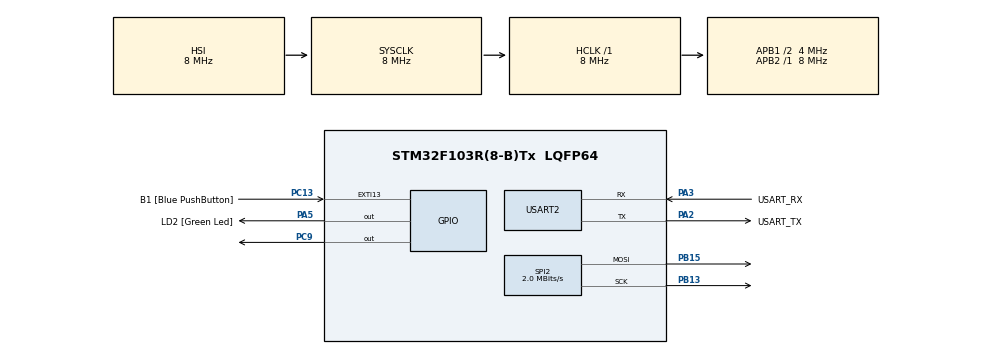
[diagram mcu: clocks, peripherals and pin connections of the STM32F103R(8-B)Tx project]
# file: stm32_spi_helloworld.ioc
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Dma.Request0=SPI2_TX
Dma.SPI2_TX.0.Direction=DMA_MEMORY_TO_PERIPH
Dma.SPI2_TX.0.Instance=DMA1_Channel5
Dma.SPI2_TX.0.MemDataAlignment=DMA_MDATAALIGN_BYTE
Dma.SPI2_TX.0.MemInc=DMA_MINC_ENABLE
Dma.SPI2_TX.0.Mode=DMA_NORMAL
Dma.SPI2_TX.0.PeriphDataAlignment=DMA_PDATAALIGN_BYTE
Dma.SPI2_TX.0.PeriphInc=DMA_PINC_DISABLE
Dma.SPI2_TX.0.Priority=DMA_PRIORITY_LOW
Mcu.Family=STM32F1
Mcu.Name=STM32F103R(8-B)Tx
Mcu.Package=LQFP64
NVIC.DMA1_Channel5_IRQn=true\:0\:0\:false\:false\:true\:false
NVIC.EXTI15_10_IRQn=true\:0\:0\:false\:false\:true\:true
NVIC.PriorityGroup=NVIC_PRIORITYGROUP_4
PA13.GPIO_Label=TMS
PA13.Mode=Serial_Wire
PA13.Signal=SYS_JTMS-SWDIO
PA14.GPIO_Label=TCK
PA14.Mode=Serial_Wire
PA14.Signal=SYS_JTCK-SWCLK
PA2.GPIO_Label=USART_TX
PA2.GPIO_Mode=GPIO_MODE_AF_PP
PA2.GPIO_PuPd=GPIO_NOPULL
PA2.GPIO_Speed=GPIO_SPEED_FREQ_LOW
PA2.Mode=Asynchronous
PA2.Signal=USART2_TX
PA3.GPIO_Label=USART_RX
PA3.GPIO_Mode=GPIO_MODE_AF_PP
PA3.GPIO_PuPd=GPIO_NOPULL
PA3.GPIO_Speed=GPIO_SPEED_FREQ_LOW
PA3.Mode=Asynchronous
PA3.Signal=USART2_RX
PA5.GPIO_Label=LD2 [Green Led]
PA5.GPIO_ModeDefaultOutputPP=GPIO_MODE_OUTPUT_PP
PA5.GPIO_PuPd=GPIO_NOPULL
PA5.GPIO_Speed=GPIO_SPEED_FREQ_LOW
PA5.Signal=GPIO_Output
PB13.Mode=TX_Only_Simplex_Unidirect_Master
PB13.Signal=SPI2_SCK
PB15.Mode=TX_Only_Simplex_Unidirect_Master
PB15.Signal=SPI2_MOSI
PB3.GPIO_Label=SWO
PB3.Signal=SYS_JTDO-TRACESWO
PC13-TAMPER-RTC.GPIO_Label=B1 [Blue PushButton]
PC13-TAMPER-RTC.GPIO_PuPd=GPIO_NOPULL
PC13-TAMPER-RTC.Signal=GPXTI13
PC14-OSC32_IN.Mode=LSE-External-Oscillator
PC14-OSC32_IN.Signal=RCC_OSC32_IN
PC15-OSC32_OUT.Mode=LSE-External-Oscillator
PC15-OSC32_OUT.Signal=RCC_OSC32_OUT
PC9.Signal=GPIO_Output
PD0-OSC_IN.Mode=HSE-External-Clock-Source
PD0-OSC_IN.Signal=RCC_OSC_IN
PD1-OSC_OUT.Mode=HSE-External-Clock-Source
PD1-OSC_OUT.Signal=RCC_OSC_OUT
ProjectManager.HeapSize=0x200
ProjectManager.StackSize=0x400
ProjectManager.TargetToolchain=Makefile
RCC.AHBFreq_Value=8000000
RCC.APB1CLKDivider=RCC_HCLK_DIV2
RCC.APB1Freq_Value=4000000
RCC.APB1TimFreq_Value=8000000
RCC.APB2Freq_Value=8000000
RCC.APB2TimFreq_Value=8000000
RCC.HCLKFreq_Value=8000000
RCC.PLLSourceVirtual=RCC_PLLSOURCE_HSE
RCC.RTCClockSelection=RCC_RTCCLKSOURCE_LSE
RCC.SYSCLKFreq_VALUE=8000000
RCC.USBFreq_Value=16000000
SPI2.CalculateBaudRate=2.0 MBits/s
SPI2.Direction=SPI_DIRECTION_2LINES
SPI2.Mode=SPI_MODE_MASTER
SPI2.VirtualType=VM_MASTER
USART2.VirtualMode=VM_ASYNC
board=NUCLEO-F103RB

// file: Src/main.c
/**
  ******************************************************************************
  * @file           : main.c
  * @brief          : Main program body
  ******************************************************************************
  ** This notice applies to any and all portions of this file
  * that are not between comment pairs USER CODE BEGIN and
  * USER CODE END. Other portions of this file, whether
  * inserted by the user or by software development tools
  * are owned by their respective copyright owners.
  *
  * COPYRIGHT(c) 2018 STMicroelectronics
  *
  * Redistribution and use in source and binary forms, with or without modification,
  * are permitted provided that the following conditions are met:
  *   1. Redistributions of source code must retain the above copyright notice,
  *      this list of conditions and the following disclaimer.
  *   2. Redistributions in binary form must reproduce the above copyright notice,
  *      this list of conditions and the following disclaimer in the documentation
  *      and/or other materials provided with the distribution.
  *   3. Neither the name of STMicroelectronics nor the names of its contributors
  *      may be used to endorse or promote products derived from this software
  *      without specific prior written permission.
  *
  * THIS SOFTWARE IS PROVIDED BY THE COPYRIGHT HOLDERS AND CONTRIBUTORS "AS IS"
  * AND ANY EXPRESS OR IMPLIED WARRANTIES, INCLUDING, BUT NOT LIMITED TO, THE
  * IMPLIED WARRANTIES OF MERCHANTABILITY AND FITNESS FOR A PARTICULAR PURPOSE ARE
  * DISCLAIMED. IN NO EVENT SHALL THE COPYRIGHT HOLDER OR CONTRIBUTORS BE LIABLE
  * FOR ANY DIRECT, INDIRECT, INCIDENTAL, SPECIAL, EXEMPLARY, OR CONSEQUENTIAL
  * DAMAGES (INCLUDING, BUT NOT LIMITED TO, PROCUREMENT OF SUBSTITUTE GOODS OR
  * SERVICES; LOSS OF USE, DATA, OR PROFITS; OR BUSINESS INTERRUPTION) HOWEVER
  * CAUSED AND ON ANY THEORY OF LIABILITY, WHETHER IN CONTRACT, STRICT LIABILITY,
  * OR TORT (INCLUDING NEGLIGENCE OR OTHERWISE) ARISING IN ANY WAY OUT OF THE USE
  * OF THIS SOFTWARE, EVEN IF ADVISED OF THE POSSIBILITY OF SUCH DAMAGE.
  *
  ******************************************************************************
  */
#include "main.h"
#include "stm32f1xx_hal.h"
#include "dma.h"
#include "spi.h"
#include "usart.h"
#include "gpio.h"

/* USER CODE BEGIN PV */
/* Private variables ---------------------------------------------------------*/

/* USER CODE END PV */

void SystemClock_Config(void);

/* USER CODE BEGIN PFP */
/* Private function prototypes -----------------------------------------------*/

/* USER CODE END PFP */

int main(void)
{

  /* MCU Configuration----------------------------------------------------------*/

  /* Reset of all peripherals, Initializes the Flash interface and the Systick. */
  HAL_Init();

  /* Configure the system clock */
  SystemClock_Config();

  /* Initialize all configured peripherals */
  MX_GPIO_Init();
  MX_DMA_Init();
  MX_USART2_UART_Init();
  MX_SPI2_Init();
  /* USER CODE BEGIN 2 */

  uint8_t test_message[5] = "AAAAA";

  /* USER CODE END 2 */

  /* Infinite loop */
  while (1)
  {

  /* USER CODE BEGIN 3 */
    // HAL_GPIO_TogglePin(LD2_GPIO_Port, LD2_Pin);
    // HAL_Delay(1000);

    // HAL_SPI_Transmit(&hspi2, &test_message, 5, 1000);
    HAL_SPI_Transmit_DMA(&hspi2, &test_message, 5);
    HAL_Delay(100);
  }
  /* USER CODE END 3 */

}

void SystemClock_Config(void)
{

  RCC_OscInitTypeDef RCC_OscInitStruct;
  RCC_ClkInitTypeDef RCC_ClkInitStruct;

    /**Initializes the CPU, AHB and APB busses clocks
    */
  RCC_OscInitStruct.OscillatorType = RCC_OSCILLATORTYPE_HSI;
  RCC_OscInitStruct.HSIState = RCC_HSI_ON;
  RCC_OscInitStruct.HSICalibrationValue = 16;
  RCC_OscInitStruct.PLL.PLLState = RCC_PLL_NONE;
  if (HAL_RCC_OscConfig(&RCC_OscInitStruct) != HAL_OK)
  {
    _Error_Handler(__FILE__, __LINE__);
  }

    /**Initializes the CPU, AHB and APB busses clocks
    */
  RCC_ClkInitStruct.ClockType = RCC_CLOCKTYPE_HCLK|RCC_CLOCKTYPE_SYSCLK
                              |RCC_CLOCKTYPE_PCLK1|RCC_CLOCKTYPE_PCLK2;
  RCC_ClkInitStruct.SYSCLKSource = RCC_SYSCLKSOURCE_HSI;
  RCC_ClkInitStruct.AHBCLKDivider = RCC_SYSCLK_DIV1;
  RCC_ClkInitStruct.APB1CLKDivider = RCC_HCLK_DIV2;
  RCC_ClkInitStruct.APB2CLKDivider = RCC_HCLK_DIV1;

  if (HAL_RCC_ClockConfig(&RCC_ClkInitStruct, FLASH_LATENCY_0) != HAL_OK)
  {
    _Error_Handler(__FILE__, __LINE__);
  }

    /**Configure the Systick interrupt time
    */
  HAL_SYSTICK_Config(HAL_RCC_GetHCLKFreq()/1000);

    /**Configure the Systick
    */
  HAL_SYSTICK_CLKSourceConfig(SYSTICK_CLKSOURCE_HCLK);

  /* SysTick_IRQn interrupt configuration */
  HAL_NVIC_SetPriority(SysTick_IRQn, 0, 0);
}

void _Error_Handler(char *file, int line)
{
  while(1)
  {
  }
}

/************************ (C) COPYRIGHT STMicroelectronics *****END OF FILE****/
